VERSION ""

NS_ :

BS_:

BU_:

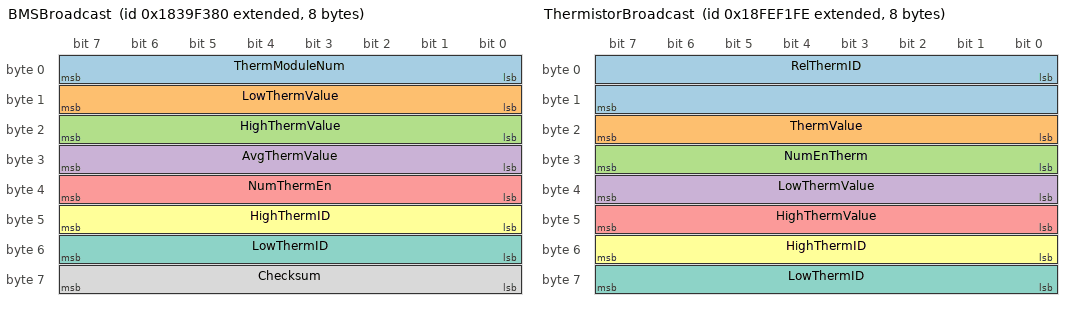
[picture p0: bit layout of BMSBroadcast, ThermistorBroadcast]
BO_ 2553934720 BMSBroadcast: 8 TMS
	SG_ ThermModuleNum : 0|8@1+ (0,0) [0|0] "" BMS
	SG_ LowThermValue : 8|8@1- (0,0) [0|0] " C" BMS
	SG_ HighThermValue : 16|8@1- (0,0) [0|0] " C" BMS
	SG_ AvgThermValue : 24|8@1- (0,0) [0|0] " C" BMS
	SG_ NumThermEn : 32|8@1+ (0,0) [0|0] "" BMS
	SG_ HighThermID : 40|8@1+ (0,0) [0|0] "" BMS
	SG_ LowThermID : 48|8@1+ (0,0) [0|0] "" BMS
	SG_ Checksum : 56|8@1- (0,0) [0|0] "" BMS

BO_ 2566844926 ThermistorBroadcast: 8 TMS
	SG_ RelThermID : 0|16@1+ (0,0) [0|0] "" BMS
	SG_ ThermValue : 16|8@1- (0,0) [0|0] " C" BMS
	SG_ NumEnTherm : 24|8@1- (0,0) [0|0] "" BMS
	SG_ LowThermValue : 32|8@1- (0,0) [0|0] " C" BMS
	SG_ HighThermValue : 40|8@1- (0,0) [0|0] " C" BMS
	SG_ HighThermID : 48|8@1+ (0,0) [0|0] "" BMS
	SG_ LowThermID : 56|8@1+ (0,0) [0|0] "" BMS

CM_ BO_ 2553934720 "Thermistor Module - BMS Broadcast";
CM_ SG_ 2553934720 ThermModuleNum "Thermistor Module Number";
CM_ BO_ 2566844926 "Thermistor General Broadcast";
CM_ SG_ 2566844926 RelThermID "Thermistor ID relative to all configured Thermistor Modules";
BA_DEF_ BO_  "VFrameFormat" ENUM  "StandardCAN","ExtendedCAN","reserved","J1939PG";
BA_DEF_  "DatabaseVersion" STRING ;
BA_DEF_  "BusType" STRING ;
BA_DEF_  "ProtocolType" STRING ;
BA_DEF_  "DatabaseCompiler" STRING ;
BA_DEF_DEF_  "VFrameFormat" "J1939PG";
BA_DEF_DEF_  "DatabaseVersion" "DEMO PLUS";
BA_DEF_DEF_  "BusType" "";
BA_DEF_DEF_  "ProtocolType" "";
BA_DEF_DEF_  "DatabaseCompiler" "";
BA_ "ProtocolType" "J1939";
BA_ "BusType" "CAN";
BA_ "DatabaseCompiler" "CSS ELECTRONICS (WWW.CSSELECTRONICS.COM)";
BA_ "DatabaseVersion" "1.0.0";
